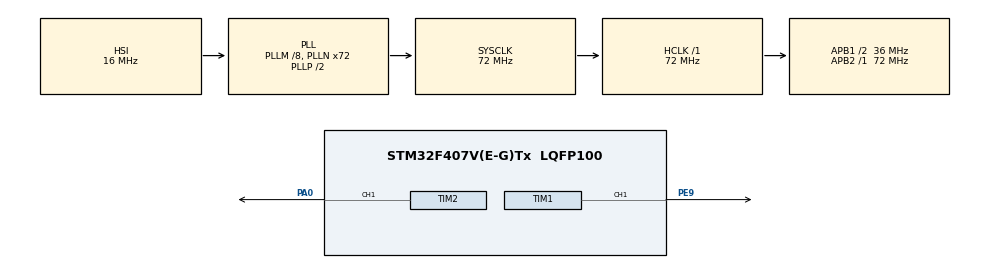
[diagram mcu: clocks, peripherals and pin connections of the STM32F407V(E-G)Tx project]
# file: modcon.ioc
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Mcu.Family=STM32F4
Mcu.Name=STM32F407V(E-G)Tx
Mcu.Package=LQFP100
NVIC.PriorityGroup=NVIC_PRIORITYGROUP_4
PA0-WKUP.Signal=S_TIM2_CH1_ETR
PE9.Signal=S_TIM1_CH1
PH0-OSC_IN.Mode=HSE-External-Oscillator
PH0-OSC_IN.Signal=RCC_OSC_IN
PH1-OSC_OUT.Mode=HSE-External-Oscillator
PH1-OSC_OUT.Signal=RCC_OSC_OUT
ProjectManager.HeapSize=0x200
ProjectManager.StackSize=0x400
ProjectManager.TargetToolchain=STM32CubeIDE
RCC.48MHZClocksFreq_Value=36000000
RCC.AHBFreq_Value=72000000
RCC.APB1CLKDivider=RCC_HCLK_DIV2
RCC.APB1Freq_Value=36000000
RCC.APB1TimFreq_Value=72000000
RCC.APB2Freq_Value=72000000
RCC.APB2TimFreq_Value=72000000
RCC.CortexFreq_Value=72000000
RCC.HCLKFreq_Value=72000000
RCC.HSE_VALUE=25000000
RCC.HSI_VALUE=16000000
RCC.LSE_VALUE=32768
RCC.PLLM=8
RCC.PLLN=72
RCC.SYSCLKFreq_VALUE=72000000
RCC.SYSCLKSource=RCC_SYSCLKSOURCE_PLLCLK
RCC.VCOOutputFreq_Value=144000000
SH.S_TIM1_CH1.0=TIM1_CH1,PWM Generation1 CH1
SH.S_TIM2_CH1_ETR.0=TIM2_CH1,PWM Generation1 CH1
TIM1.AutoReloadPreload=TIM_AUTORELOAD_PRELOAD_ENABLE
TIM1.Channel-PWM\ Generation1\ CH1=TIM_CHANNEL_1
TIM2.AutoReloadPreload=TIM_AUTORELOAD_PRELOAD_ENABLE
TIM2.Channel-PWM\ Generation1\ CH1=TIM_CHANNEL_1
TIM2.Period=65535
VP_TIM1_VS_ClockSourceINT.Mode=Internal
VP_TIM2_VS_ClockSourceINT.Mode=Internal
board=custom

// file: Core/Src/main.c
/* USER CODE BEGIN Header */
/**
  ******************************************************************************
  * @file           : main.c
  * @brief          : Main program body
  ******************************************************************************
  * @attention
  *
  * Copyright (c) 2026 STMicroelectronics.
  * All rights reserved.
  *
  * This software is licensed under terms that can be found in the LICENSE file
  * in the root directory of this software component.
  * If no LICENSE file comes with this software, it is provided AS-IS.
  *
  ******************************************************************************
  */
/* USER CODE END Header */
#include "main.h"

TIM_HandleTypeDef htim1;
TIM_HandleTypeDef htim2;

void SystemClock_Config(void);
static void MX_GPIO_Init(void);
static void MX_TIM1_Init(void);
static void MX_TIM2_Init(void);

int main(void)
{

  /* USER CODE BEGIN 1 */
	int32_t dutyCycle;
  /* USER CODE END 1 */

  /* MCU Configuration--------------------------------------------------------*/

  /* Reset of all peripherals, Initializes the Flash interface and the Systick. */
  HAL_Init();

  /* Configure the system clock */
  SystemClock_Config();

  /* Initialize all configured peripherals */
  MX_GPIO_Init();
  MX_TIM1_Init();
  MX_TIM2_Init();
  HAL_TIM_PWM_Start(&htim2, TIM_CHANNEL_1);

  /* Infinite loop */
  while (1)
  {
	   while(dutyCycle < 65535)
	        {
	            TIM2->CCR1 = dutyCycle;
	            dutyCycle += 100;
	            HAL_Delay(2);
	        }
	        while(dutyCycle > 0)
	        {
	            TIM2->CCR1 = dutyCycle;
	            dutyCycle -= 100;
	            HAL_Delay(2);
	        }
  }
}

void SystemClock_Config(void)
{
  RCC_OscInitTypeDef RCC_OscInitStruct = {0};
  RCC_ClkInitTypeDef RCC_ClkInitStruct = {0};

  /** Configure the main internal regulator output voltage
  */
  __HAL_RCC_PWR_CLK_ENABLE();
  __HAL_PWR_VOLTAGESCALING_CONFIG(PWR_REGULATOR_VOLTAGE_SCALE1);

  /** Initializes the RCC Oscillators according to the specified parameters
  * in the RCC_OscInitTypeDef structure.
  */
  RCC_OscInitStruct.OscillatorType = RCC_OSCILLATORTYPE_HSI;
  RCC_OscInitStruct.HSIState = RCC_HSI_ON;
  RCC_OscInitStruct.HSICalibrationValue = RCC_HSICALIBRATION_DEFAULT;
  RCC_OscInitStruct.PLL.PLLState = RCC_PLL_ON;
  RCC_OscInitStruct.PLL.PLLSource = RCC_PLLSOURCE_HSI;
  RCC_OscInitStruct.PLL.PLLM = 8;
  RCC_OscInitStruct.PLL.PLLN = 72;
  RCC_OscInitStruct.PLL.PLLP = RCC_PLLP_DIV2;
  RCC_OscInitStruct.PLL.PLLQ = 4;
  if (HAL_RCC_OscConfig(&RCC_OscInitStruct) != HAL_OK)
  {
    Error_Handler();
  }

  /** Initializes the CPU, AHB and APB buses clocks
  */
  RCC_ClkInitStruct.ClockType = RCC_CLOCKTYPE_HCLK|RCC_CLOCKTYPE_SYSCLK
                              |RCC_CLOCKTYPE_PCLK1|RCC_CLOCKTYPE_PCLK2;
  RCC_ClkInitStruct.SYSCLKSource = RCC_SYSCLKSOURCE_PLLCLK;
  RCC_ClkInitStruct.AHBCLKDivider = RCC_SYSCLK_DIV1;
  RCC_ClkInitStruct.APB1CLKDivider = RCC_HCLK_DIV2;
  RCC_ClkInitStruct.APB2CLKDivider = RCC_HCLK_DIV1;

  if (HAL_RCC_ClockConfig(&RCC_ClkInitStruct, FLASH_LATENCY_2) != HAL_OK)
  {
    Error_Handler();
  }
}

static void MX_TIM1_Init(void)
{

  TIM_ClockConfigTypeDef sClockSourceConfig = {0};
  TIM_MasterConfigTypeDef sMasterConfig = {0};
  TIM_OC_InitTypeDef sConfigOC = {0};
  TIM_BreakDeadTimeConfigTypeDef sBreakDeadTimeConfig = {0};

  htim1.Instance = TIM1;
  htim1.Init.Prescaler = 0;
  htim1.Init.CounterMode = TIM_COUNTERMODE_UP;
  htim1.Init.Period = 65535;
  htim1.Init.ClockDivision = TIM_CLOCKDIVISION_DIV1;
  htim1.Init.RepetitionCounter = 0;
  htim1.Init.AutoReloadPreload = TIM_AUTORELOAD_PRELOAD_ENABLE;
  if (HAL_TIM_Base_Init(&htim1) != HAL_OK)
  {
    Error_Handler();
  }
  sClockSourceConfig.ClockSource = TIM_CLOCKSOURCE_INTERNAL;
  if (HAL_TIM_ConfigClockSource(&htim1, &sClockSourceConfig) != HAL_OK)
  {
    Error_Handler();
  }
  if (HAL_TIM_PWM_Init(&htim1) != HAL_OK)
  {
    Error_Handler();
  }
  sMasterConfig.MasterOutputTrigger = TIM_TRGO_RESET;
  sMasterConfig.MasterSlaveMode = TIM_MASTERSLAVEMODE_DISABLE;
  if (HAL_TIMEx_MasterConfigSynchronization(&htim1, &sMasterConfig) != HAL_OK)
  {
    Error_Handler();
  }
  sConfigOC.OCMode = TIM_OCMODE_PWM1;
  sConfigOC.Pulse = 0;
  sConfigOC.OCPolarity = TIM_OCPOLARITY_HIGH;
  sConfigOC.OCNPolarity = TIM_OCNPOLARITY_HIGH;
  sConfigOC.OCFastMode = TIM_OCFAST_DISABLE;
  sConfigOC.OCIdleState = TIM_OCIDLESTATE_RESET;
  sConfigOC.OCNIdleState = TIM_OCNIDLESTATE_RESET;
  if (HAL_TIM_PWM_ConfigChannel(&htim1, &sConfigOC, TIM_CHANNEL_1) != HAL_OK)
  {
    Error_Handler();
  }
  sBreakDeadTimeConfig.OffStateRunMode = TIM_OSSR_DISABLE;
  sBreakDeadTimeConfig.OffStateIDLEMode = TIM_OSSI_DISABLE;
  sBreakDeadTimeConfig.LockLevel = TIM_LOCKLEVEL_OFF;
  sBreakDeadTimeConfig.DeadTime = 0;
  sBreakDeadTimeConfig.BreakState = TIM_BREAK_DISABLE;
  sBreakDeadTimeConfig.BreakPolarity = TIM_BREAKPOLARITY_HIGH;
  sBreakDeadTimeConfig.AutomaticOutput = TIM_AUTOMATICOUTPUT_DISABLE;
  if (HAL_TIMEx_ConfigBreakDeadTime(&htim1, &sBreakDeadTimeConfig) != HAL_OK)
  {
    Error_Handler();
  }
  HAL_TIM_MspPostInit(&htim1);

}

static void MX_TIM2_Init(void)
{

  TIM_ClockConfigTypeDef sClockSourceConfig = {0};
  TIM_MasterConfigTypeDef sMasterConfig = {0};
  TIM_OC_InitTypeDef sConfigOC = {0};

  htim2.Instance = TIM2;
  htim2.Init.Prescaler = 0;
  htim2.Init.CounterMode = TIM_COUNTERMODE_UP;
  htim2.Init.Period = 65535;
  htim2.Init.ClockDivision = TIM_CLOCKDIVISION_DIV1;
  htim2.Init.AutoReloadPreload = TIM_AUTORELOAD_PRELOAD_ENABLE;
  if (HAL_TIM_Base_Init(&htim2) != HAL_OK)
  {
    Error_Handler();
  }
  sClockSourceConfig.ClockSource = TIM_CLOCKSOURCE_INTERNAL;
  if (HAL_TIM_ConfigClockSource(&htim2, &sClockSourceConfig) != HAL_OK)
  {
    Error_Handler();
  }
  if (HAL_TIM_PWM_Init(&htim2) != HAL_OK)
  {
    Error_Handler();
  }
  sMasterConfig.MasterOutputTrigger = TIM_TRGO_RESET;
  sMasterConfig.MasterSlaveMode = TIM_MASTERSLAVEMODE_DISABLE;
  if (HAL_TIMEx_MasterConfigSynchronization(&htim2, &sMasterConfig) != HAL_OK)
  {
    Error_Handler();
  }
  sConfigOC.OCMode = TIM_OCMODE_PWM1;
  sConfigOC.Pulse = 0;
  sConfigOC.OCPolarity = TIM_OCPOLARITY_HIGH;
  sConfigOC.OCFastMode = TIM_OCFAST_DISABLE;
  if (HAL_TIM_PWM_ConfigChannel(&htim2, &sConfigOC, TIM_CHANNEL_1) != HAL_OK)
  {
    Error_Handler();
  }
  HAL_TIM_MspPostInit(&htim2);

}

static void MX_GPIO_Init(void)
{

  /* GPIO Ports Clock Enable */
  __HAL_RCC_GPIOH_CLK_ENABLE();
  __HAL_RCC_GPIOA_CLK_ENABLE();
  __HAL_RCC_GPIOE_CLK_ENABLE();

}

void Error_Handler(void)
{
  __disable_irq();
  while (1)
  {
  }
}
